# YTM32B1HA0 register map
Vendor: YTMicro; File version: 1.0
CPU: little endian, MPU, FPU, 2 interrupt priority bits
Registers are 32-bit, read-write, reset 0x0 unless marked. A register's access mark holds for its fields unless they carry their own. Offsets are from the block's base; [hi:lo] are bit positions; {n}, {i} and the like mark numbered series; 'fields as' and 'values as' point back to an identical list.

## QSPI — Quad Serial Peripheral Interface
Base 0x401A0000; register names take the prefix QSPI_
0x00 MEN
  [0] EN — Module enable/disable control.
    0=Module is disabled or disabled after current operation done; 1=Module is enabled
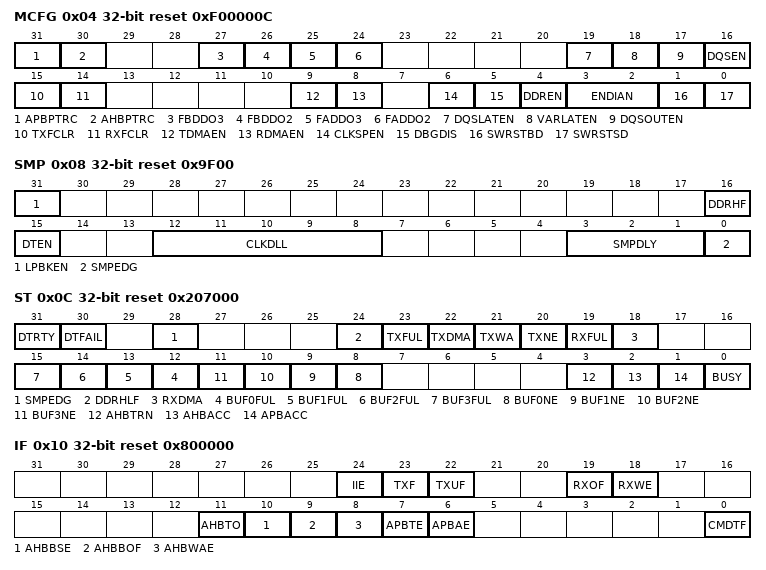
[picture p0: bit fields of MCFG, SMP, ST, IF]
0x04 MCFG reset 0xF00000C
  [31] APBPTRC wo — Write 1 to clear LUT sequence point for APB access.
    0=No action; 1=LUT sequence point is reset to 0
  [30] AHBPTRC wo — Write 1 to clear LUT sequence point for AHB access.
    0=No action; 1=LUT sequence point is reset to 0
  [27] FBDDO3 — Define the data 3 output default value of flash B. It's effective in 1/2 line mode. This bit can only be changed when MEN[EN]=0.
    0=Data 3 output low in 1/2 line mode; 1=Data 3 output high in 1/2 line mode
  [26] FBDDO2 — Define the data 2 output default value of flash B. It's effective in 1/2 line mode. This bit can only be changed when MEN[EN]=0.
    0=Data 2 output low in 1/2 line mode; 1=Data 2 output high in 1/2 line mode
  [25] FADDO3 — Define the data 3 output default value of flash A. It's effective in 1/2 line mode. This bit can only be changed when MEN[EN]=0.
    values as FBDDO3
  [24] FADDO2 — Define the data 2 output default value of flash A. It's effective in 1/2 line mode. This bit can only be changed when MEN[EN]=0.
    values as FBDDO2
  [19] DQSLATEN — Select sample data store way in DQS sample mode.
    0=No latency store, sample data stored each time is not greater than 64 bits, it's up to configured data size; 1=Latency store, sample data stored each time is every 64 bits
  [18] VARLATEN — Configure this bit to adapt additional latency insertion. Only used in HyperRAM device.
    0=Variable latency is disabled; 1=Variable latency is enabled
  [17] DQSOUTEN — Enable/disable DQS output during write operation. DQS can only output low.
    0=DQS output is disabled; 1=DQS output is enabled
  [16] DQSEN — Enable/disable DQS write/read mode. Only used in HyperFlash/HyperRAM.
    0=DQS write/read is disabled; 1=DQS write/read is enabled
  [15] TXFCLR wo — Write 1 to clear TxFIFO data.
    0=No action; 1=Clear TxFIFO data
  [14] RXFCLR wo — Write 1 to clear RxFIFO data.
    0=No action; 1=Clear RxFIFO data
  [9] TDMAEN — Enable/disable transmit DMA.
    0=Transmit DMA is disabled; 1=Transmit DMA is enabled
  [8] RDMAEN — Enable/disable receive DMA.
    0=Receive DMA is disabled; 1=Receive DMA is enabled
  [6] CLKSPEN — Enable/disable clock output stop when RxFIFO full.
    0=Clock output stop is disabled; 1=Clock output stop is enabled
  [5] DBGDIS — Module disable control under debug mode.
    0=No action when the chip enters debug mode; 1=Disable the module after current operation done when the chip enters debug mode
  [4] DDREN — DDR mode write/read enable.
    0=DDR mode is disabled; 1=DDR mode is enabled
  [3:2] ENDIAN — Define endian format of reading data.
    0=No swapping; 1=Byte swapping in 32 bit; 2=Word swapping in 64 bit; 3=Word swapping in 64 bit and byte swapping in 32 bit
  [1] SWRSTBD — Reset all bus domain logics. Clear by manual.
    0=Stop reset action; 1=Start reset action
  [0] SWRSTSD — Reset all serial flash domain logics. Clear by manual.
    0=Stop reset action; 1=Start reset action
0x08 SMP reset 0x9F00 — This register can only be changed when MEN[EN]=0.
  [31] LPBKEN — Enable/disable loopback sample.
    0=Loopback sample is disabled; 1=Loopback sample is enabled
  [16] DDRHF — Half cycle sample offset in DDR mode. This field only works when SMP[DTEN]=0.
    0=Sampling without offset, the first sample edge is rising edge in DDR mode; 1=Sampling with half cycle offset, the first sample edge is falling edge in DDR mode
  [15] DTEN — Enable/disable data test mode.
    0=Data test is disabled, sampling data with configuration of registers; 1=Data test is enabled, sampling data with the result of data test
  [12:8] CLKDLL — Configure the delay cell number in loopback clock or DQS clock input path. Each delay cell is about 180~540ps. Delay cell number is value + 1, value 0 means no delay. This field only works in loopback sample mode or DQS sample mode.
  [3:1] SMPDLY — Configure the sample delay point, offset on the serial flash clock cycle. Value 0 is no offset, value 7 is the max offset. This field only works when SMP[DTEN]=0.
  [0] SMPEDG — Select the sample edge for input data. This field only works when SMP[DTEN]=0.
    0=Sampling on rising edge in SDR mode, and the first sample edge is rising edge in DQS mode; 1=Sampling on falling edge in SDR mode, and the first sample edge is falling edge in DQS mode
0x0C ST reset 0x207000
  [31] DTRTY ro — Data test retry indication.
    0=Don't care; 1=Need retry the DATA TEST instruction
  [30] DTFAIL ro — Data test fail indicator.
    0=Don't care; 1=DATA TEST is failed, no valid data is sampled
  [28] SMPEDG ro — Sample edge indicator.
    0=SDR mode sample edge is rising edge, or the first sample edge is rising edge in DQS mode; 1=SDR mode sample edge is falling edge, or the first sample edge is falling edge in DQS mode
  [24] DDRHLF ro — Half cycle sample offset indicator in DDR mode.
    values as SMP.DDRHF
  [23] TXFUL ro — TxFIFO full indicator.
    0=TxFIFO is not full; 1=TxFIFO is full
  [22] TXDMA ro — TxFIFO DMA busy indicator.
    0=TxFIFO is not under DMA access; 1=TxFIFO is under DMA access
  [21] TXWA ro — TxFIFO watermark available indicator.
    0=TxFIFO empty space is not greater than the watermark; 1=TxFIFO empty space is greater than the watermark
  [20] TXNE ro — TxFIFO not empty indicator.
    0=TxFIFO data number is less than 4; 1=TxFIFO data number is not less than 4
  [19] RXFUL ro — RxFIFO full indicator.
    0=RxFIFO is not full; 1=RxFIFO is full
  [18] RXDMA ro — RxFIFO DMA busy indicator.
    0=RxFIFO is not under DMA access; 1=RxFIFO is under DMA access
  [n+12] BUF{n}FUL ro (n=0..3) — Buffer {n} full indicator.
    0=Buffer {n} is not full; 1=Buffer {n} is full
  [n+8] BUF{n}NE ro (n=0..3) — Buffer {n} not empty indicator.
    0=Buffer {n} is empty; 1=Buffer {n} is not empty
  [3] AHBTRN ro — AHB transmit indictor.
    0=No AHB transmit; 1=AHB transmit is ongoing
  [2] AHBACC ro — AHB access serial flash indictor.
    0=Serial flash is not under AHB access; 1=Serial flash is under AHB access
  [1] APBACC ro — APB access serial flash indictor.
    0=Serial flash is not under APB access; 1=Serial flash is under APB access
  [0] BUSY ro — Serial flash busy indicator.
    0=Serial flash is idle; 1=Serial flash is under AHB or APB access
0x10 IF reset 0x800000
  [24] IIE — Illegal instruction indicator.
    0=No error detected; 1=Illegal instruction detected
  [23] TXF — Before writing to the TxFIFO, this field should be cleared. Then, it should be read back.
    0=TxFIFO can be considered as full; 1=TxFIFO is not full and can fill in more data
  [22] TXUF — TxFIFO underflow indicator.
    0=No underflow detected; 1=Underflow detected
  [19] RXOF — RxFIFO overflow indicator.
    0=No overflow detected; 1=Overflow detected
  [18] RXWE — RxFIFO data number exceed watermark indicator.
    0=RxFIFO data number is not greater than the watermark; 1=RxFIFO data number is greater than the watermark
  [11] AHBTO — AHB access timeout indicator. If OSPI has no response to the AHB access after the time specified by AHBCFG[AHBWT], this flag will be set.
    0=No AHB access timeout detected; 1=AHB access timeout detected
  [10] AHBBSE — AHB burst size error indicator. If burst size greater than the data size, this flag will set.
    0=No error detected; 1=AHB burst size error detected
  [9] AHBBOF — AHB current buffer overflow indicator.
    0=No buffer overflow detected; 1=Buffer overflow detected
  [8] AHBWAE — AHB write access error indicator.
    0=No error detected; 1=AHB write access detected
  [7] APBTE — APB command trigger during AHB access error indicator.
    0=No error detected; 1=APB command trigger detected during AHB access the serial flash
  [6] APBAE — Illegal register access during APB access error indicator.
    0=No error detected; 1=Write access to the APBCFG/SFA/RBCS register detected during APB access the serial flash
  [0] CMDTF — LUT command transfer finish indicator.
    0=LUT command transfer is ongoing or no transfer; 1=LUT command transfer finish
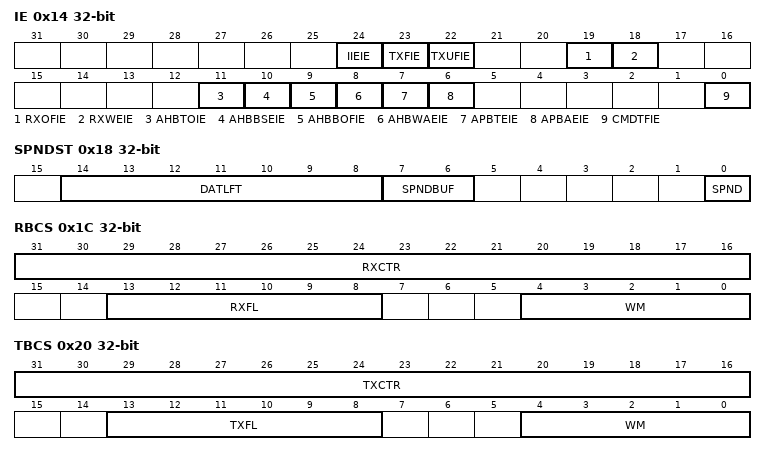
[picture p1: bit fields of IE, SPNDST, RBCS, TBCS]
0x14 IE
  [all] fields
    0=Interrupt is disabled; 1=Interrupt is enabled
  [24] IIEIE — Interrupt enable/disable control.
  [23] TXFIE — Interrupt enable/disable control.
  [22] TXUFIE — Interrupt enable/disable control.
  [19] RXOFIE — Interrupt enable/disable control.
  [18] RXWEIE — Interrupt enable/disable control.
  [11] AHBTOIE — Interrupt enable/disable control.
  [10] AHBBSEIE — Interrupt enable/disable control.
  [9] AHBBOFIE — Interrupt enable/disable control.
  [8] AHBWAEIE — Interrupt enable/disable control.
  [7] APBTEIE — Interrupt enable/disable control.
  [6] APBAEIE — Interrupt enable/disable control.
  [0] CMDTFIE — Interrupt enable/disable control.
0x18 SPNDST ro
  [14:8] DATLFT rw — Suspended data left indicator, in 64 bit. Value 0 indicate the left data is less than 64 bits.
  [7:6] SPNDBUF rw — Suspended buffer indicator.
    {v}=Buffer {v} is suspended (v=0..3)
  [0] SPND rw — Suspend state indicator.
    0=No suspend occurs; 1=Suspend occurs
0x1C RBCS
  [31:16] RXCTR ro — RxFIFO read data counter, in 32 bit. Value 1 indicate 4 bytes data have been read out from RxFIFO. This counter is incremented by the number (RBCS[WM]+1). This filed can be cleared by MCFG[RXFCLR].
  [13:8] RXFL ro — Current RxFIFO data number indicator, in 32 bit. Value 1 indicate current RxFIFO data number is 4 bytes. This filed can be cleared by MCFG[RXFCLR].
  [4:0] WM — RxFIFO watermark, fill lever > watermark will trigger the DMA or interrupt.
0x20 TBCS
  [31:16] TXCTR ro — TxFIFO write data counter, in 32 bit. Value 1 indicate 4 bytes data have been written into TxFIFO. This filed can be cleared by MCFG[TXFCLR].
  [13:8] TXFL ro — Current TxFIFO data number indicator, in 32 bit. Value 1 indicate current TxFIFO data number is 4 bytes. This filed can be cleared by MCFG[TXFCLR].
  [4:0] WM — TxFIFO watermark, (max TxFIFO depth - fill lever) > watermark will trigger the DMA or interrupt.
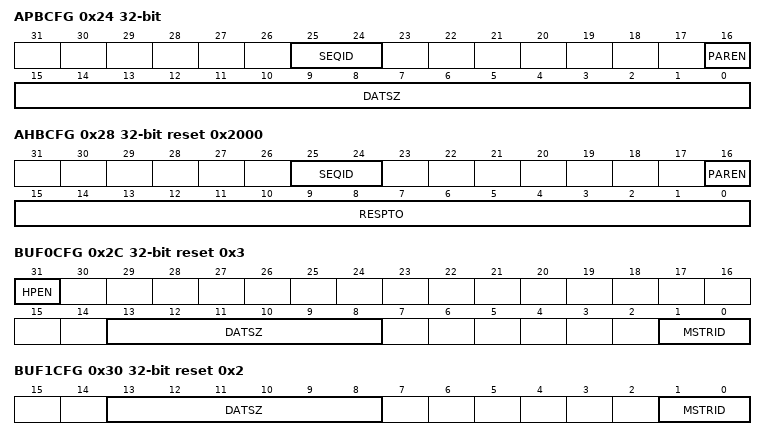
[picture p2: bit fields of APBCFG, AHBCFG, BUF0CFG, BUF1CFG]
0x24 APBCFG
  [25:24] SEQID — Select the LUT sequence when access to the serial flash by APB. A write to this field will trigger the transaction.
  [16] PAREN — Enable/disable the parallel mode when access to serial flash by APB.
    0=Parallel mode is disabled; 1=Parallel mode is enabled
  [15:0] DATSZ — Data size of APB write/read access to the serial flash, in 8 bit. Value 1 indicate the write/read data is one byte. When this field is value 0, the write/read data size is up to the operand of the write/read LUT command.
0x28 AHBCFG reset 0x2000
  [25:24] SEQID — Select the LUT sequence when access to the serial flash by AHB.
  [16] PAREN — Enable/disable the parallel mode when access to serial flash by AHB.
    0=Parallel mode is disabled; 1=Parallel mode is enabled
  [15:0] RESPTO — Max wait time for AHB access. This field can only be changed when MEN[EN]=0. AHB write/read access to the serial flash will timeout if data not transmitted or no data received after RESPTO*1024 AHB clock cycles.
0x2C BUF0CFG reset 0x3
  [31] HPEN — Buffer 0 high priority enable/disable control.
    0=Buffer 0 is same as other buffers; 1=Buffer 0 has higher priority than other buffers, access to buffer 0 will result in other buffers' access being suspended
  [13:8] DATSZ — Data size of AHB write/read access to the serial flash, in 64 bit. Value 1 indicate the write/read data is 8 bytes. When this field is value 0, the write/read data size is up to the operand of the write/read LUT command.
  [1:0] MSTRID — Define the AHB master ID which can access to the buffer 0.
0x30 BUF1CFG reset 0x2
  [13:8] DATSZ — Data size of AHB write/read access to the serial flash, in 64 bit. Value 1 indicate the write/read data is 8 bytes. When this field is value 0, the write/read data size is up to the operand of the write/read LUT command.
  [1:0] MSTRID — Define the AHB master ID which can access to the buffer 1.
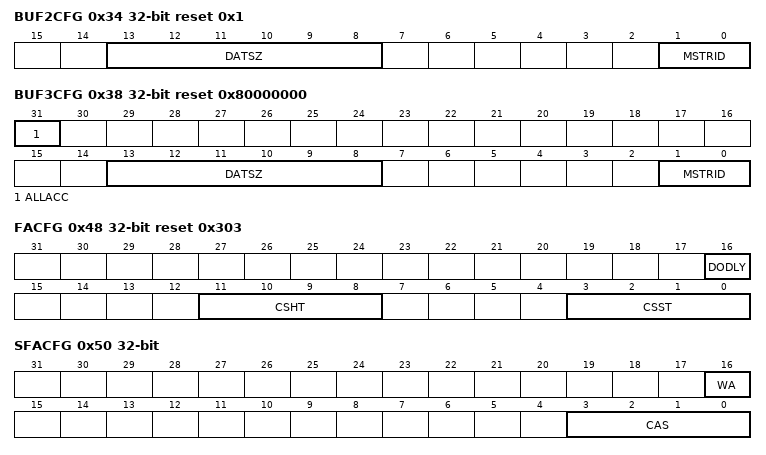
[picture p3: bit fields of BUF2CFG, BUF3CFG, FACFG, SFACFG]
0x34 BUF2CFG reset 0x1
  [13:8] DATSZ — Data size of AHB write/read access to the serial flash, in 64 bit. Value 1 indicate the write/read data is 8 bytes. When this field is value 0, the write/read data size is up to the operand of the write/read LUT command.
  [1:0] MSTRID — Define the AHB master ID which can access to the buffer 2.
0x38 BUF3CFG reset 0x80000000
  [31] ALLACC — Buffer 3 all master access enable/disable control.
    0=Buffer 3 can only be accessed by matched AHB master that defined by BUF3CFG[MSTRID]; 1=Buffer 3 can be accessed by all AHB masters
  [13:8] DATSZ — Data size of AHB write/read access to the serial flash, in 64 bit. Value 1 indicate the write/read data is 8 bytes. When this field is value 0, the write/read data size is up to the operand of the write/read LUT command.
  [1:0] MSTRID — Define the AHB master ID which can access to the buffer 3, this field is meaningless when BUF3CFG[ALLACC]=1.
0x3C BUF0IND
  [7:0] TPIND0 — Define the buffer 0 space range, sram address from 0 to (BUF0IND[TPIND0]-1) is the buffer 0 space.
0x40 BUF1IND
  [7:0] TPIND1 — Define the buffer 1 space range, sram address from BUF0IND[TPIND0] to (BUF1IND[TPIND1]-1) is the buffer 1 space.
0x44 BUF2IND
  [7:0] TPIND2 — Define the buffer 2 space range, sram address from BUF1IND[TPIND1] to (BUF2IND[TPIND2]-1) is the buffer 2 space.
0x48 FACFG reset 0x303
  [16] DODLY — Data output delay control in DDR mode.
    0=Data output is aligned to the clock edge in DDR mode; 1=Data output is 1/4 serial flash clock cycle later than the clock edge in DDR mode
  [11:8] CSHT — Define the chip select signal rises hold time that controls the chip select signal rises opportunity after clock output end.
  [3:0] CSST — Define the chip select signal falls setup time that controls the chip select signal falls opportunity before clock output start.
0x4C SFA
  [31:0] SFA — Define the serial flash access address. It's only used by APB access.
0x50 SFACFG
  [16] WA — Word address access enable/disable control.
    0=Word address access is disabled, the serial flash is accessed by byte address; 1=Word address access is enabled, the serial flash is accessed by half-word address
  [3:0] CAS — Define the column address space in address phase. The column address locate at the end of communication address.
0x54 SFA1TA reset 0x6C000000
  [31:10] SFA1TA — Define the flash A1 top address, flash A1 address access space is from 0x68000000 to SFA1TA[SFA1TA].
0x58 SFA2TA reset 0x6C000000 — Because this chip doesn't support flash A2 port, the value of this register should be same with SFA1TA register.
  [31:10] SFA2TA — Define the flash A2 top address, flash A2 address access space is from SFA1TA[SFA1TA] to SFA2TA[SFA2TA].
0x5C SFB1TA reset 0x70000000
  [31:10] SFB1TA — Define the flash B1 top address, flash B1 address access space is from SFA2TA[SFA2TA] to SFB1TA[SFB1TA].
0x60 SFB2TA reset 0x70000000 — Because this chip doesn't support flash B2 port, the value of this register should be same with SFB1TA register.
  [31:10] SFB2TA — Define the flash B2 top address, flash B2 address access space is from SFB1TA[SFB1TA] to SFB2TA[SFB2TA].
0x64 DTPR reset 0x5A691E78
  [31:0] DTPR — Define the pattern that used for data test check.
0x7C TXDAT
  [31:0] TXDAT — This register provides access to the TxFIFO. On a read access. the last written data will be returned.
{0x80+4i} RXDAT{i} (i=0..31) — These registers provide read access to all RxFIFO received data, the first received data locates at RXDAT0 register.
  [31:0] RXDAT — This register contains the data of RxFIFO.
0x100 LUTKEY reset 0x5AF05AF0 — This register is only used for protecting LOCK register. Writing correct key to this register will close the protection, and access to register except LOCK register will active the protection.
  [31:0] LUTKEY — Write this register to lock or unlock the LUT. The key is 0x5AF05AF0 and the read value is always 0x5AF05AF0.
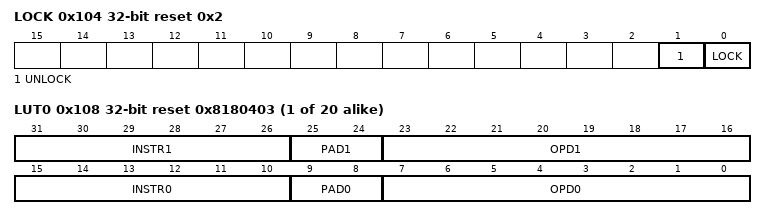
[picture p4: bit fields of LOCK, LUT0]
0x104 LOCK reset 0x2 — This register can only access after writing correct key to LUTKEY register.
  [1] UNLOCK — Unlock the LUT write access.
    0=Write access to LUT registers is invalid; 1=Write access to LUT registers is valid
  [0] LOCK — Lock the LUT write access.
    0=Write access to LUT registers is valid; 1=Write access to LUT registers is invalid
{0x108+4i} LUT{i} reset 0x8180403 (i=0..19) — LUT0 reset value is 0x08180403, LUT1 reset value is 0x3C002008, other LUTs' reset value are 0x00000000.
  [31:26] INSTR1 — Define the instruction that expect this module to execute.
  [25:24] PAD1 — PAD information for INSTR1.
    0=one pad; 1=two pads; 2=four pads; 3=eight pads
  [23:16] OPD1 — Operand for INSTR1.
  [15:10] INSTR0 — Define the instruction that expect this module to execute.
  [9:8] PAD0 — PAD information for INSTR0.
    0=one pad; 1=two pads; 2=four pads; 3=eight pads
  [7:0] OPD0 — Operand for INSTR0.
